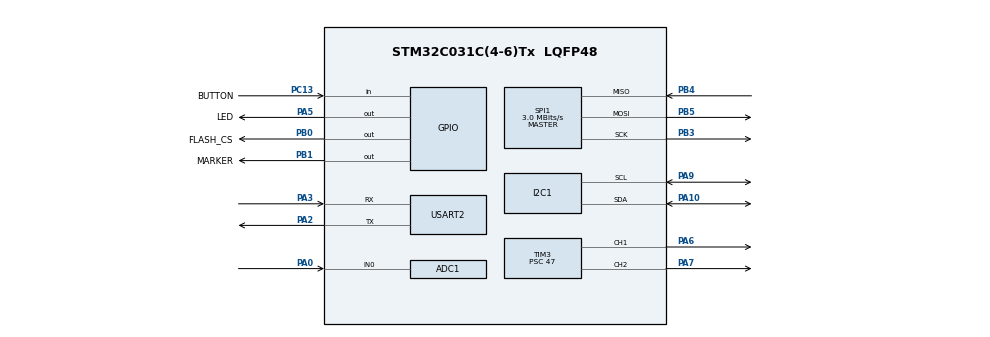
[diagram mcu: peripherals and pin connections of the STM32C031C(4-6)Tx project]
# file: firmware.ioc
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ADC1.NbrOfConversionFlag=0
ADC1.SelectedChannel=ADC_CHANNEL_0
ADC1.master=1
I2C1.Timing=0x10805D88
Mcu.Family=STM32C0
Mcu.Name=STM32C031C(4-6)Tx
Mcu.Package=LQFP48
PA0.Mode=IN0
PA0.Signal=ADC1_IN0
PA10.Mode=I2C
PA10.Signal=I2C1_SDA
PA13.GPIO_Label=DEBUG_SWDIO
PA13.Signal=DEBUG_SWDIO
PA14-BOOT0.GPIO_Label=DEBUG_SWCLK
PA14-BOOT0.Signal=DEBUG_SWCLK
PA2.Mode=Asynchronous
PA2.Signal=USART2_TX
PA3.Mode=Asynchronous
PA3.Signal=USART2_RX
PA5.GPIO_Label=LED
PA5.Signal=GPIO_Output
PA6.Signal=S_TIM3_CH1
PA7.Signal=S_TIM3_CH2
PA9.Mode=I2C
PA9.Signal=I2C1_SCL
PB0.GPIO_Label=FLASH_CS
PB0.PinState=GPIO_PIN_SET
PB0.Signal=GPIO_Output
PB1.GPIO_Label=MARKER
PB1.Signal=GPIO_Output
PB3.Mode=Full_Duplex_Master
PB3.Signal=SPI1_SCK
PB4.Mode=Full_Duplex_Master
PB4.Signal=SPI1_MISO
PB5.Mode=Full_Duplex_Master
PB5.Signal=SPI1_MOSI
PC13.GPIO_Label=BUTTON
PC13.GPIO_PuPd=GPIO_PULLUP
PC13.Signal=GPIO_Input
PC14-OSCX_IN\ (PC14).GPIO_Label=RCC_OSCX_IN
PC14-OSCX_IN\ (PC14).Mode=LSE-External-Oscillator
PC14-OSCX_IN\ (PC14).Signal=RCC_OSCX_IN
PC15-OSCX_OUT\ (PC15).GPIO_Label=RCC_OSCX_OUT
PC15-OSCX_OUT\ (PC15).Mode=LSE-External-Oscillator
PC15-OSCX_OUT\ (PC15).Signal=RCC_OSCX_OUT
PF0-OSC_IN\ (PF0).GPIO_Label=RCC_OSC_IN
PF0-OSC_IN\ (PF0).Mode=HSE-External-Oscillator
PF0-OSC_IN\ (PF0).Signal=RCC_OSC_IN
PF1-OSC_OUT\ (PF1).GPIO_Label=RCC_OSC_OUT
PF1-OSC_OUT\ (PF1).Mode=HSE-External-Oscillator
PF1-OSC_OUT\ (PF1).Signal=RCC_OSC_OUT
ProjectManager.HeapSize=0x200
ProjectManager.StackSize=0x400
ProjectManager.TargetToolchain=Makefile
RCC.ADCFreq_Value=48000000
RCC.AHBFreq_Value=48000000
RCC.CortexFreq_Value=48000000
RCC.EXTERNAL_CLOCK_VALUE=12288000
RCC.HCLKFreq_Value=48000000
RCC.HSE_VALUE=48000000
RCC.HSISYSCLKDivider=RCC_HSI_DIV1
RCC.HSI_VALUE=48000000
RCC.SYSCLKFreq_VALUE=48000000
SH.S_TIM3_CH1.0=TIM3_CH1,PWM Generation1 CH1
SH.S_TIM3_CH2.0=TIM3_CH2,PWM Generation2 CH2
SPI1.BaudRatePrescaler=SPI_BAUDRATEPRESCALER_16
SPI1.CalculateBaudRate=3.0 MBits/s
SPI1.Direction=SPI_DIRECTION_2LINES
SPI1.Mode=SPI_MODE_MASTER
SPI1.VirtualType=VM_MASTER
TIM3.Channel-PWM\ Generation1\ CH1=TIM_CHANNEL_1
TIM3.Channel-PWM\ Generation2\ CH2=TIM_CHANNEL_2
TIM3.Period=19999
TIM3.Prescaler=47
USART2.VirtualMode-Asynchronous=VM_ASYNC
board=NUCLEO-C031C6

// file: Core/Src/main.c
/* USER CODE BEGIN Header */
/**
  ******************************************************************************
  * @file           : main.c
  * @brief          : Main program body
  ******************************************************************************
  * @attention
  *
  * Copyright (c) 2026 STMicroelectronics.
  * All rights reserved.
  *
  * This software is licensed under terms that can be found in the LICENSE file
  * in the root directory of this software component.
  * If no LICENSE file comes with this software, it is provided AS-IS.
  *
  ******************************************************************************
  */
/* USER CODE END Header */
#include "main.h"

/* USER CODE BEGIN Includes */
#include "app.h"
#include "platform.h"

  /* USER CODE END Includes */

ADC_HandleTypeDef hadc1;

I2C_HandleTypeDef hi2c1;

SPI_HandleTypeDef hspi1;

TIM_HandleTypeDef htim3;

UART_HandleTypeDef huart2;

void SystemClock_Config(void);
static void MX_GPIO_Init(void);
static void MX_ADC1_Init(void);
static void MX_I2C1_Init(void);
static void MX_SPI1_Init(void);
static void MX_TIM3_Init(void);
static void MX_USART2_UART_Init(void);

int main(void)
{

  /* MCU Configuration--------------------------------------------------------*/

  /* Reset of all peripherals, Initializes the Flash interface and the Systick. */
  HAL_Init();

  /* Configure the system clock */
  SystemClock_Config();

  /* Initialize all configured peripherals */
  MX_GPIO_Init();
  MX_ADC1_Init();
  MX_I2C1_Init();
  MX_SPI1_Init();
  MX_TIM3_Init();
  MX_USART2_UART_Init();
  /* USER CODE BEGIN 2 */
  /* Layers: Platform (HAL adaptation) -> App (business logic). main.c only wires them. */
  platform_init();
  app_init(platform_ports());
  app_boot();

  /* USER CODE END 2 */

  /* Infinite loop */
  while (1)
  {

    /* USER CODE BEGIN 3 */
    app_poll();
    /* USER CODE END 3 */
  }
}

void SystemClock_Config(void)
{
  RCC_OscInitTypeDef RCC_OscInitStruct = {0};
  RCC_ClkInitTypeDef RCC_ClkInitStruct = {0};

  __HAL_FLASH_SET_LATENCY(FLASH_LATENCY_1);

  /** Initializes the RCC Oscillators according to the specified parameters
  * in the RCC_OscInitTypeDef structure.
  */
  RCC_OscInitStruct.OscillatorType = RCC_OSCILLATORTYPE_HSI;
  RCC_OscInitStruct.HSIState = RCC_HSI_ON;
  RCC_OscInitStruct.HSIDiv = RCC_HSI_DIV1;
  RCC_OscInitStruct.HSICalibrationValue = RCC_HSICALIBRATION_DEFAULT;
  if (HAL_RCC_OscConfig(&RCC_OscInitStruct) != HAL_OK)
  {
    Error_Handler();
  }

  /** Initializes the CPU, AHB and APB buses clocks
  */
  RCC_ClkInitStruct.ClockType = RCC_CLOCKTYPE_HCLK|RCC_CLOCKTYPE_SYSCLK
                              |RCC_CLOCKTYPE_PCLK1;
  RCC_ClkInitStruct.SYSCLKSource = RCC_SYSCLKSOURCE_HSI;
  RCC_ClkInitStruct.SYSCLKDivider = RCC_SYSCLK_DIV1;
  RCC_ClkInitStruct.AHBCLKDivider = RCC_HCLK_DIV1;
  RCC_ClkInitStruct.APB1CLKDivider = RCC_APB1_DIV1;

  if (HAL_RCC_ClockConfig(&RCC_ClkInitStruct, FLASH_LATENCY_1) != HAL_OK)
  {
    Error_Handler();
  }
}

static void MX_ADC1_Init(void)
{

  ADC_ChannelConfTypeDef sConfig = {0};

  /** Configure the global features of the ADC (Clock, Resolution, Data Alignment and number of conversion)
  */
  hadc1.Instance = ADC1;
  hadc1.Init.ClockPrescaler = ADC_CLOCK_SYNC_PCLK_DIV2;
  hadc1.Init.Resolution = ADC_RESOLUTION_12B;
  hadc1.Init.DataAlign = ADC_DATAALIGN_RIGHT;
  hadc1.Init.ScanConvMode = ADC_SCAN_SEQ_FIXED;
  hadc1.Init.EOCSelection = ADC_EOC_SINGLE_CONV;
  hadc1.Init.LowPowerAutoWait = DISABLE;
  hadc1.Init.LowPowerAutoPowerOff = DISABLE;
  hadc1.Init.ContinuousConvMode = DISABLE;
  hadc1.Init.NbrOfConversion = 1;
  hadc1.Init.DiscontinuousConvMode = DISABLE;
  hadc1.Init.ExternalTrigConv = ADC_SOFTWARE_START;
  hadc1.Init.ExternalTrigConvEdge = ADC_EXTERNALTRIGCONVEDGE_NONE;
  hadc1.Init.DMAContinuousRequests = DISABLE;
  hadc1.Init.Overrun = ADC_OVR_DATA_PRESERVED;
  hadc1.Init.SamplingTimeCommon1 = ADC_SAMPLETIME_1CYCLE_5;
  hadc1.Init.OversamplingMode = DISABLE;
  hadc1.Init.TriggerFrequencyMode = ADC_TRIGGER_FREQ_HIGH;
  if (HAL_ADC_Init(&hadc1) != HAL_OK)
  {
    Error_Handler();
  }

  /** Configure Regular Channel
  */
  sConfig.Channel = ADC_CHANNEL_0;
  sConfig.Rank = ADC_RANK_CHANNEL_NUMBER;
  if (HAL_ADC_ConfigChannel(&hadc1, &sConfig) != HAL_OK)
  {
    Error_Handler();
  }

}

static void MX_I2C1_Init(void)
{

  hi2c1.Instance = I2C1;
  hi2c1.Init.Timing = 0x10805D88;
  hi2c1.Init.OwnAddress1 = 0;
  hi2c1.Init.AddressingMode = I2C_ADDRESSINGMODE_7BIT;
  hi2c1.Init.DualAddressMode = I2C_DUALADDRESS_DISABLE;
  hi2c1.Init.OwnAddress2 = 0;
  hi2c1.Init.OwnAddress2Masks = I2C_OA2_NOMASK;
  hi2c1.Init.GeneralCallMode = I2C_GENERALCALL_DISABLE;
  hi2c1.Init.NoStretchMode = I2C_NOSTRETCH_DISABLE;
  if (HAL_I2C_Init(&hi2c1) != HAL_OK)
  {
    Error_Handler();
  }

  /** Configure Analogue filter
  */
  if (HAL_I2CEx_ConfigAnalogFilter(&hi2c1, I2C_ANALOGFILTER_ENABLE) != HAL_OK)
  {
    Error_Handler();
  }

  /** Configure Digital filter
  */
  if (HAL_I2CEx_ConfigDigitalFilter(&hi2c1, 0) != HAL_OK)
  {
    Error_Handler();
  }

}

static void MX_SPI1_Init(void)
{

  /* SPI1 parameter configuration*/
  hspi1.Instance = SPI1;
  hspi1.Init.Mode = SPI_MODE_MASTER;
  hspi1.Init.Direction = SPI_DIRECTION_2LINES;
  hspi1.Init.DataSize = SPI_DATASIZE_8BIT;
  hspi1.Init.CLKPolarity = SPI_POLARITY_LOW;
  hspi1.Init.CLKPhase = SPI_PHASE_1EDGE;
  hspi1.Init.NSS = SPI_NSS_SOFT;
  hspi1.Init.BaudRatePrescaler = SPI_BAUDRATEPRESCALER_16;
  hspi1.Init.FirstBit = SPI_FIRSTBIT_MSB;
  hspi1.Init.TIMode = SPI_TIMODE_DISABLE;
  hspi1.Init.CRCCalculation = SPI_CRCCALCULATION_DISABLE;
  hspi1.Init.CRCPolynomial = 7;
  hspi1.Init.CRCLength = SPI_CRC_LENGTH_DATASIZE;
  hspi1.Init.NSSPMode = SPI_NSS_PULSE_ENABLE;
  if (HAL_SPI_Init(&hspi1) != HAL_OK)
  {
    Error_Handler();
  }

}

static void MX_TIM3_Init(void)
{

  TIM_MasterConfigTypeDef sMasterConfig = {0};
  TIM_OC_InitTypeDef sConfigOC = {0};

  htim3.Instance = TIM3;
  htim3.Init.Prescaler = 47;
  htim3.Init.CounterMode = TIM_COUNTERMODE_UP;
  htim3.Init.Period = 19999;
  htim3.Init.ClockDivision = TIM_CLOCKDIVISION_DIV1;
  htim3.Init.AutoReloadPreload = TIM_AUTORELOAD_PRELOAD_DISABLE;
  if (HAL_TIM_PWM_Init(&htim3) != HAL_OK)
  {
    Error_Handler();
  }
  sMasterConfig.MasterOutputTrigger = TIM_TRGO_RESET;
  sMasterConfig.MasterSlaveMode = TIM_MASTERSLAVEMODE_DISABLE;
  if (HAL_TIMEx_MasterConfigSynchronization(&htim3, &sMasterConfig) != HAL_OK)
  {
    Error_Handler();
  }
  sConfigOC.OCMode = TIM_OCMODE_PWM1;
  sConfigOC.Pulse = 0;
  sConfigOC.OCPolarity = TIM_OCPOLARITY_HIGH;
  sConfigOC.OCFastMode = TIM_OCFAST_DISABLE;
  if (HAL_TIM_PWM_ConfigChannel(&htim3, &sConfigOC, TIM_CHANNEL_1) != HAL_OK)
  {
    Error_Handler();
  }
  if (HAL_TIM_PWM_ConfigChannel(&htim3, &sConfigOC, TIM_CHANNEL_2) != HAL_OK)
  {
    Error_Handler();
  }
  HAL_TIM_MspPostInit(&htim3);

}

static void MX_USART2_UART_Init(void)
{

  huart2.Instance = USART2;
  huart2.Init.BaudRate = 115200;
  huart2.Init.WordLength = UART_WORDLENGTH_8B;
  huart2.Init.StopBits = UART_STOPBITS_1;
  huart2.Init.Parity = UART_PARITY_NONE;
  huart2.Init.Mode = UART_MODE_TX_RX;
  huart2.Init.HwFlowCtl = UART_HWCONTROL_NONE;
  huart2.Init.OverSampling = UART_OVERSAMPLING_16;
  huart2.Init.OneBitSampling = UART_ONE_BIT_SAMPLE_DISABLE;
  huart2.Init.ClockPrescaler = UART_PRESCALER_DIV1;
  huart2.AdvancedInit.AdvFeatureInit = UART_ADVFEATURE_NO_INIT;
  if (HAL_UART_Init(&huart2) != HAL_OK)
  {
    Error_Handler();
  }

}

static void MX_GPIO_Init(void)
{
  GPIO_InitTypeDef GPIO_InitStruct = {0};

  /* GPIO Ports Clock Enable */
  __HAL_RCC_GPIOC_CLK_ENABLE();
  __HAL_RCC_GPIOF_CLK_ENABLE();
  __HAL_RCC_GPIOA_CLK_ENABLE();
  __HAL_RCC_GPIOB_CLK_ENABLE();

  /*Configure GPIO pin Output Level */
  HAL_GPIO_WritePin(LED_GPIO_Port, LED_Pin, GPIO_PIN_RESET);

  /*Configure GPIO pin Output Level */
  HAL_GPIO_WritePin(FLASH_CS_GPIO_Port, FLASH_CS_Pin, GPIO_PIN_SET);

  /*Configure GPIO pin Output Level */
  HAL_GPIO_WritePin(MARKER_GPIO_Port, MARKER_Pin, GPIO_PIN_RESET);

  /*Configure GPIO pin : BUTTON_Pin */
  GPIO_InitStruct.Pin = BUTTON_Pin;
  GPIO_InitStruct.Mode = GPIO_MODE_INPUT;
  GPIO_InitStruct.Pull = GPIO_PULLUP;
  HAL_GPIO_Init(BUTTON_GPIO_Port, &GPIO_InitStruct);

  /*Configure GPIO pin : LED_Pin */
  GPIO_InitStruct.Pin = LED_Pin;
  GPIO_InitStruct.Mode = GPIO_MODE_OUTPUT_PP;
  GPIO_InitStruct.Pull = GPIO_NOPULL;
  GPIO_InitStruct.Speed = GPIO_SPEED_FREQ_LOW;
  HAL_GPIO_Init(LED_GPIO_Port, &GPIO_InitStruct);

  /*Configure GPIO pins : FLASH_CS_Pin MARKER_Pin */
  GPIO_InitStruct.Pin = FLASH_CS_Pin|MARKER_Pin;
  GPIO_InitStruct.Mode = GPIO_MODE_OUTPUT_PP;
  GPIO_InitStruct.Pull = GPIO_NOPULL;
  GPIO_InitStruct.Speed = GPIO_SPEED_FREQ_LOW;
  HAL_GPIO_Init(GPIOB, &GPIO_InitStruct);

}

void Error_Handler(void)
{
  __disable_irq();
  while (1)
  {
  }
}
